# NUC100DN_v1 register map
File version: 1.0
Registers are 32-bit, read-write, reset 0x0 unless marked. A register's access mark holds for its fields unless they carry their own. Offsets are from the block's base; [hi:lo] are bit positions; 'fields as' and 'values as' point back to an identical list.

## TMR23 — TIMER Register Map
Base 0x40110000
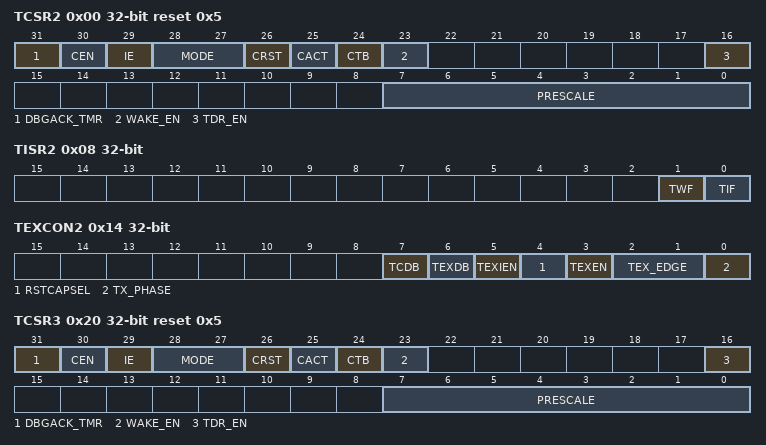
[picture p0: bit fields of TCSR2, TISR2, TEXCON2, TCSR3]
0x00 TCSR2 reset 0x5 — Timer2 Control and Status Register
  [31] DBGACK_TMR — ICE Debug Mode Acknowledge Disable Bit (Write Protect). TIMER counter will keep going no matter CPU is held by ICE or not.
    0=ICE debug mode acknowledgement effects TIMER counting; 1=ICE debug mode acknowledgement disabled
  [30] CEN — Timer Enable Bit
    0=Stops/Suspends counting; 1=Starts counting
  [29] IE — Interrupt Enable Bit. If this bit is enabled, when the timer interrupt flag (TISR[0] TIF) is set to 1, the timer interrupt signal is generated and inform to CPU.
    0=Timer Interrupt Disabled; 1=Timer Interrupt Enabled
  [28:27] MODE — Timer Operating Mode
    0=The Timer controller is operated in One-shot mode. Please refer to 6.8.4.1 for detail description; 1=The Timer controller is operated in Periodic mode. Please refer to 6.8.4.2 for detail description; 2=The Timer controller is operated in Toggle-output mode. Please refer to 6.8.4.3 for detail description; 3=The Timer controller is operated in Continuous Counting mode. Please refer to 6.8.4.4 for detail description
  [26] CRST — Timer Reset Bit. Setting this bit will reset the 24-bit up counter value (TDR) and also force CEN (TCSR[30] timer enable bit) to 0 if CACT (TCSR[25] timer active status bit) is 1.
    0=No effect; 1=Reset 8-bit prescale counter, 24-bit up counter value and CEN bit
  [25] CACT ro — Timer Active Status Bit (Read Only). This bit indicates the 24-bit up counter status.
    0=24-bit up counter is not active; 1=24-bit up counter is active
  [24] CTB — Counter Mode Enable Bit. This bit is for external counting pin function enabled. When timer is used as an event counter, this bit should be set to 1 and select HCLK as timer clock source. Please refer to 6.8.4.5 for detail description.
    0=External counter mode Disabled; 1=External counter mode Enabled
  [23] WAKE_EN — Wake-up Enable Bit. If this bit is set to 1, while timer interrupt flag (TISR[0] TIF) is generated to 1 and IE (TCSR[29] interrupt enable bit) is enabled, the timer interrupt signal will generate a wake-up trigger event to CPU.
    0=Wake-up trigger event Disabled if timer interrupt signal generated; 1=Wake-up trigger event Enabled if timer interrupt signal generated
  [16] TDR_EN — Data Load Enable Bit. When this bit is set, timer counter value (TDR) will be updated continuously to monitor internal 24-bit up counter value as the counter is counting.
    0=Timer Data Register update Disabled; 1=Timer Data Register update Enabled while timer counter is active
  [7:0] PRESCALE — Prescale Counter
0x04 TCMPR2 — Timer2 Compare Register
  [23:0] TCMP — Timer Compared Value. TCMP is a 24-bit compared value register. When the internal 24-bit up counter value is equal to TCMP value, the TIF (TISR[0] timet interrupt flag) will set to 1. Note1: Never write 0x0 or 0x1 in TCMP field, or the core will run into unknown state. Note2: When timer is operating at continuous counting mode, the 24-bit up counter will keep counting continuously even if software writes a new value into TCMP field. But if timer is operating at other modes, the 24-bit up counter will restart counting and using newest TCMP value to be the timer compared value if software writes a new value into TCMP field.
0x08 TISR2 — Timer2 Interrupt Status Register
  [1] TWF — Timer Wake-up Flag. This bit indicates the interrupt wake-up flag status of timer. Note: This bit is cleared by writing 1 to it.
    0=Timer does not cause CPU wake-up; 1=CPU wake-up from Idle or power-down mode if timer interrupt signal generated
  [0] TIF — Timer Interrupt Flag. This bit indicates the interrupt flag status of Timer. And this bit is set by hardware when the timer counter value) matches the timer compared value (TCMP value). Note: This bit is cleared by writing 1 to it.
0x0C TDR2 ro — Timer2 Data Register
  [23:0] TDR — Timer Data Register. If TDR_EN (TCSR[16]) is set to 1, TDR will be updated continuously to monitor 24-bit timer counter value.
0x10 TCAP2 ro — Timer2 Capture Data Register
  [23:0] TCAP — Timer Capture Data Register. When TEXEN (TEXCON[3] timer external pin enable) bit is set, RSTCAPSEL (TEXCON[4] timer external reset counter/capture mode select) bit is 0, and a transition on TxEX pin matched the TEX_EDGE (TEXCON[2:1] timer external pin edge detect) setting, TEXIF (TEXISR[0] timer external interrupt flag) will set to 1 and the current timer counter value (TDR value) will be auto-loaded into this TCAP field.
0x14 TEXCON2 — Timer2 External Control Register
  [7] TCDB — Timer Counter Pin De-bounce Enable Bit. Note: If this bit is enabled, the edge detection of TMx pin is detected with de-bounce circuit.
    0=TMx pin de-bounce Disabled; 1=TMx pin de-bounce Enabled
  [6] TEXDB — Timer External Capture Pin De-bounce Enable Bit. Note: If this bit is enabled, the edge detection of TxEX pin is detected with de-bounce circuit.
    0=TxEX pin de-bounce Disabled; 1=TxEX pin de-bounce Enabled
  [5] TEXIEN — Timer External Interrupt Enable Bit
    0=TxEX pin detection Interrupt Disabled; 1=TxEX pin detection Interrupt Enabled
  [4] RSTCAPSEL — Timer External Reset Counter / Capture Mode Selection
    0=Transition on TxEX pin is using to save the 24-bit timer counter value (TDR value) to timer capture value (TCAP value) if TEXIF (TEXISR[0] timer external interrupt flag) is set to 1; 1=Transition on TxEX pin is using to reset the 24-bit timer counter
  [3] TEXEN — Timer External Pin Enable Bit. This bit enables the RSTCAPSEL (TEXCON[4] timer external reset counter/capture mode select ) function on the TxEX pin.
    0=RSTCAPSEL function of TxEX pin will be ignored; 1=RSTCAPSEL function of TxEX pin is active
  [2:1] TEX_EDGE — Timer External Pin Edge Detect
    0=A 1 to 0 transition on TxEX pin will be detected; 1=A 0 to 1 transition on TxEX pin will be detected; 2=Either 1 to 0 or 0 to 1 transition on TxEX pin will be detected
  [0] TX_PHASE — Timer External Count Phase. This bit indicates the detection phase of external counting pin.
    0=A falling edge of external counting pin will be counted; 1=A rising edge of external counting pin will be counted
0x18 TEXISR2 — Timer2 External Interrupt Status Register
  [0] TEXIF — Timer External Interrupt Flag. This bit indicates the timer external interrupt flag status. When TEXEN (TEXCON[3] timer external pin enable) bit is set, RSTCAPSEL (TEXCON[4] timer external reset counter/capture mode select) bit is 0, and a transition on TxEX pin matched the TEX_EDGE (TEXCON[2:1] timer external pin edge detect) setting, this bit will set to 1 by hardware. Note: This bit is cleared by writing 1 to it.
0x20 TCSR3 reset 0x5 — Timer3 Control and Status Register
  fields as TCSR2
0x24 TCMPR3 — Timer3 Compare Register
  fields as TCMPR2
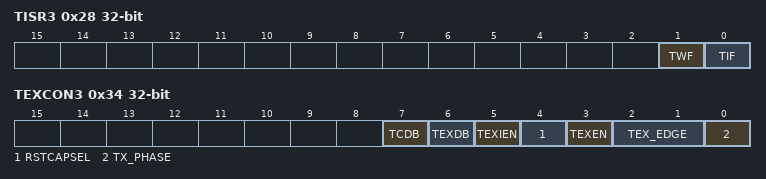
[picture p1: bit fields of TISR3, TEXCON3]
0x28 TISR3 — Timer3 Interrupt Status Register
  fields as TISR2
0x2C TDR3 ro — Timer3 Data Register
  fields as TDR2
0x30 TCAP3 ro — Timer3 Capture Data Register
  fields as TCAP2
0x34 TEXCON3 — Timer3 External Control Register
  fields as TEXCON2
0x38 TEXISR3 — Timer3 External Interrupt Status Register
  fields as TEXISR2
